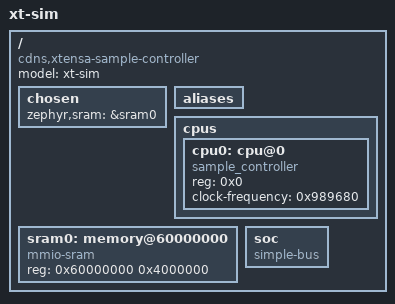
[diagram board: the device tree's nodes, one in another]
/dts-v1/;

/* node '/' defined in zephyr/dts/common/skeleton.dtsi:9 */
/ {
	#address-cells = < 0x1 >;                     /* in zephyr/dts/common/skeleton.dtsi:10 */
	#size-cells = < 0x1 >;                        /* in zephyr/dts/common/skeleton.dtsi:11 */
	model = "xt-sim";                             /* in zephyr/boards/cdns/xt-sim/xt-sim.dts:11 */
	compatible = "cdns,xtensa-sample-controller"; /* in zephyr/boards/cdns/xt-sim/xt-sim.dts:12 */

	/* node '/chosen' defined in zephyr/dts/common/skeleton.dtsi:13 */
	chosen {
		zephyr,sram = &sram0; /* in zephyr/boards/cdns/xt-sim/xt-sim.dts:15 */
	};

	/* node '/aliases' defined in zephyr/dts/common/skeleton.dtsi:15 */
	aliases {
	};

	/* node '/cpus' defined in zephyr/dts/xtensa/sample_controller.dtsi:10 */
	cpus {
		#address-cells = < 0x1 >; /* in zephyr/dts/xtensa/sample_controller.dtsi:11 */
		#size-cells = < 0x0 >;    /* in zephyr/dts/xtensa/sample_controller.dtsi:12 */

		/* node '/cpus/cpu@0' defined in zephyr/dts/xtensa/sample_controller.dtsi:14 */
		cpu0: cpu@0 {
			device_type = "cpu";              /* in zephyr/dts/xtensa/sample_controller.dtsi:15 */
			compatible = "sample_controller"; /* in zephyr/dts/xtensa/sample_controller.dtsi:16 */
			reg = < 0x0 >;                    /* in zephyr/dts/xtensa/sample_controller.dtsi:17 */
			clock-frequency = < 0x989680 >;   /* in zephyr/boards/cdns/xt-sim/xt-sim.dts:20 */
		};
	};

	/* node '/memory@60000000' defined in zephyr/dts/xtensa/sample_controller.dtsi:21 */
	sram0: memory@60000000 {
		device_type = "memory";         /* in zephyr/dts/xtensa/sample_controller.dtsi:22 */
		compatible = "mmio-sram";       /* in zephyr/dts/xtensa/sample_controller.dtsi:23 */
		reg = < 0x60000000 0x4000000 >; /* in zephyr/dts/xtensa/sample_controller.dtsi:24 */
	};

	/* node '/soc' defined in zephyr/dts/xtensa/sample_controller.dtsi:27 */
	soc {
		#address-cells = < 0x1 >;  /* in zephyr/dts/xtensa/sample_controller.dtsi:28 */
		#size-cells = < 0x1 >;     /* in zephyr/dts/xtensa/sample_controller.dtsi:29 */
		compatible = "simple-bus"; /* in zephyr/dts/xtensa/sample_controller.dtsi:30 */
		ranges;                    /* in zephyr/dts/xtensa/sample_controller.dtsi:31 */
	};
};
